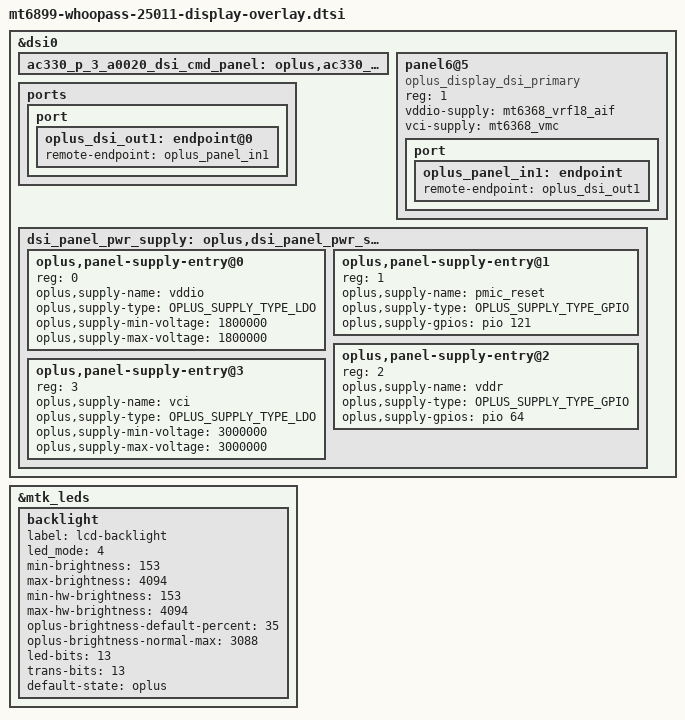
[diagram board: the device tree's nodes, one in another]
#include "mt6899-dsi-display-conf.h"
#include "ac330-p-3-a0020-dsi-cmd-panel-ext-params.dtsi"

&dsi0 {
	ac330_p_3_a0020_dsi_cmd_panel: oplus,ac330_p_3_a0020_dsi_cmd_panel {};
};

#include "ac330-p-3-a0020-dsi-cmd-panel-cmd.dtsi"

&mtk_leds {
	status = "okay";

	backlight {
		label = "lcd-backlight";
		led_mode = <4>;
		min-brightness = <153>;
		max-brightness = <4094>;
		min-hw-brightness = <153>;
		max-hw-brightness = <4094>;
		oplus-brightness-default-percent = <35>;
		oplus-brightness-normal-max = <3088>;
		led-bits = <13>;
		trans-bits = <13>;
		default-state = "oplus";
	};
};

&dsi0 {
	status = "okay";
	#address-cells = <1>;
	#size-cells = <0>;
	/* choose second panel which support spr */
	/* choose MTK SPR IP */
	panel6@5 {
		compatible = "oplus_display_dsi_primary";
		reg = <1>;
		vddio-supply = <&mt6368_vrf18_aif>;
		vci-supply = <&mt6368_vmc>;
		pinctrl-names = "default";
		port {
			oplus_panel_in1: endpoint {
				remote-endpoint = <&oplus_dsi_out1>;
			};
		};
	};

	ports {
		port {
			oplus_dsi_out1: endpoint@0 {
				remote-endpoint = <&oplus_panel_in1>;
			};
		};
	};
};

&dsi0 {
	dsi_panel_pwr_supply: oplus,dsi_panel_pwr_supply {
		oplus,panel-supply-entry@0 {
			reg = <0>;
			oplus,supply-name = "vddio";
			oplus,supply-type = <OPLUS_SUPPLY_TYPE_LDO>;
			oplus,supply-min-voltage = <1800000>;
			oplus,supply-max-voltage = <1800000>;
		};
		oplus,panel-supply-entry@1 {
			reg = <1>;
			oplus,supply-name = "pmic_reset";
			oplus,supply-type = <OPLUS_SUPPLY_TYPE_GPIO>;
			oplus,supply-gpios = <&pio 121 0>;
		};
		oplus,panel-supply-entry@2 {
			reg = <2>;
			oplus,supply-name = "vddr";
			oplus,supply-type = <OPLUS_SUPPLY_TYPE_GPIO>;
			oplus,supply-gpios = <&pio 64 0>;
		};
		oplus,panel-supply-entry@3 {
			reg = <3>;
			oplus,supply-name = "vci";
			oplus,supply-type = <OPLUS_SUPPLY_TYPE_LDO>;
			oplus,supply-min-voltage = <3000000>;
			oplus,supply-max-voltage = <3000000>;
		};
	};
};
